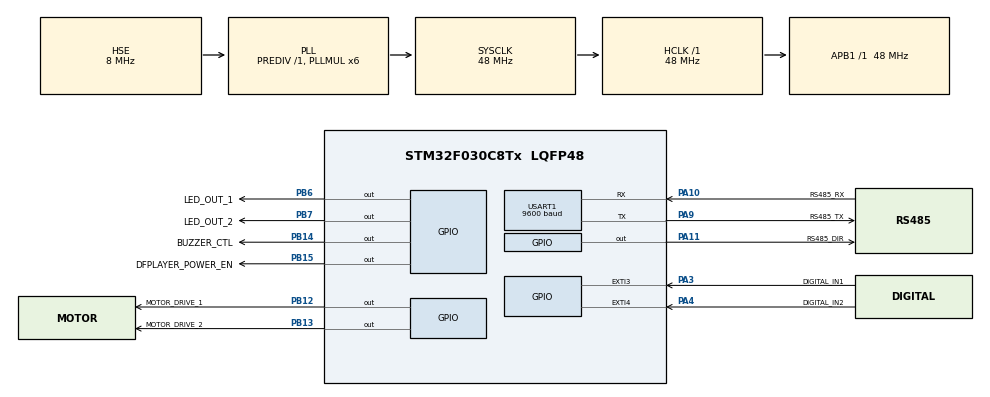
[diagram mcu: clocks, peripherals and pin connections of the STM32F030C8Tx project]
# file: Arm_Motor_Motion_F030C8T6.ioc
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Mcu.Family=STM32F0
Mcu.Name=STM32F030C8Tx
Mcu.Package=LQFP48
NVIC.EXTI2_3_IRQn=true\:0\:0\:false\:false\:true\:true\:true\:true
NVIC.EXTI4_15_IRQn=true\:0\:0\:false\:false\:true\:true\:true\:true
NVIC.USART1_IRQn=true\:0\:0\:false\:false\:true\:true\:true\:true
PA10.GPIO_Label=RS485_RX
PA10.Mode=Asynchronous
PA10.Signal=USART1_RX
PA11.GPIO_Label=RS485_DIR
PA11.Signal=GPIO_Output
PA13.GPIO_Label=TMS
PA13.Mode=Serial_Wire
PA13.Signal=SYS_SWDIO
PA14.GPIO_Label=TCK
PA14.Mode=Serial_Wire
PA14.Signal=SYS_SWCLK
PA3.GPIO_Label=DIGITAL_IN1
PA3.GPIO_ModeDefaultEXTI=GPIO_MODE_IT_RISING_FALLING
PA3.Signal=GPXTI3
PA4.GPIO_Label=DIGITAL_IN2
PA4.Signal=GPXTI4
PA9.GPIO_Label=RS485_TX
PA9.Mode=Asynchronous
PA9.Signal=USART1_TX
PB12.GPIO_Label=MOTOR_DRIVE_1
PB12.Signal=GPIO_Output
PB13.GPIO_Label=MOTOR_DRIVE_2
PB13.Signal=GPIO_Output
PB14.GPIO_Label=BUZZER_CTL
PB14.Signal=GPIO_Output
PB15.GPIO_Label=DFPLAYER_POWER_EN
PB15.Signal=GPIO_Output
PB6.GPIO_Label=LED_OUT_1
PB6.PinState=GPIO_PIN_RESET
PB6.Signal=GPIO_Output
PB7.GPIO_Label=LED_OUT_2
PB7.PinState=GPIO_PIN_RESET
PB7.Signal=GPIO_Output
PF0-OSC_IN.GPIO_Label=OSC_IN
PF0-OSC_IN.Mode=HSE-External-Oscillator
PF0-OSC_IN.Signal=RCC_OSC_IN
PF1-OSC_OUT.GPIO_Label=OSC_OUT
PF1-OSC_OUT.Mode=HSE-External-Oscillator
PF1-OSC_OUT.Signal=RCC_OSC_OUT
ProjectManager.HeapSize=0x200
ProjectManager.StackSize=0x400
ProjectManager.TargetToolchain=STM32CubeIDE
RCC.AHBFreq_Value=48000000
RCC.APB1Freq_Value=48000000
RCC.APB1TimFreq_Value=48000000
RCC.HCLKFreq_Value=48000000
RCC.PLLMUL=RCC_PLL_MUL6
RCC.PLLSourceVirtual=RCC_PLLSOURCE_HSE
RCC.SYSCLKFreq_VALUE=48000000
RCC.SYSCLKSource=RCC_SYSCLKSOURCE_PLLCLK
USART1.BaudRate=9600
USART1.VirtualMode-Asynchronous=VM_ASYNC
board=custom

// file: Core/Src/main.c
/* USER CODE BEGIN Header */
/**
  ******************************************************************************
  * @file           : main.c
  * @brief          : Main program body
  ******************************************************************************
  * @attention
  *
  * Copyright (c) 2024 STMicroelectronics.
  * All rights reserved.
  *
  * This software is licensed under terms that can be found in the LICENSE file
  * in the root directory of this software component.
  * If no LICENSE file comes with this software, it is provided AS-IS.
  *
  ******************************************************************************
  */
/* USER CODE END Header */
#include "main.h"

UART_HandleTypeDef huart1;

void SystemClock_Config(void);
static void MX_GPIO_Init(void);
static void MX_USART1_UART_Init(void);

int main(void)
{

  /* MCU Configuration--------------------------------------------------------*/

  /* Reset of all peripherals, Initializes the Flash interface and the Systick. */
  HAL_Init();

  /* Configure the system clock */
  SystemClock_Config();

  /* Initialize all configured peripherals */
  MX_GPIO_Init();
  MX_USART1_UART_Init();
  /* USER CODE BEGIN 2 */
  motor_motion_init();
  /* USER CODE END 2 */

  /* Infinite loop */
  while (1)
  {

    /* USER CODE BEGIN 3 */
	  motor_motion_control();
  }
  /* USER CODE END 3 */
}

void SystemClock_Config(void)
{
  RCC_OscInitTypeDef RCC_OscInitStruct = {0};
  RCC_ClkInitTypeDef RCC_ClkInitStruct = {0};
  RCC_PeriphCLKInitTypeDef PeriphClkInit = {0};

  /** Initializes the RCC Oscillators according to the specified parameters
  * in the RCC_OscInitTypeDef structure.
  */
  RCC_OscInitStruct.OscillatorType = RCC_OSCILLATORTYPE_HSE;
  RCC_OscInitStruct.HSEState = RCC_HSE_ON;
  RCC_OscInitStruct.PLL.PLLState = RCC_PLL_ON;
  RCC_OscInitStruct.PLL.PLLSource = RCC_PLLSOURCE_HSE;
  RCC_OscInitStruct.PLL.PLLMUL = RCC_PLL_MUL6;
  RCC_OscInitStruct.PLL.PREDIV = RCC_PREDIV_DIV1;
  if (HAL_RCC_OscConfig(&RCC_OscInitStruct) != HAL_OK)
  {
    Error_Handler();
  }

  /** Initializes the CPU, AHB and APB buses clocks
  */
  RCC_ClkInitStruct.ClockType = RCC_CLOCKTYPE_HCLK|RCC_CLOCKTYPE_SYSCLK
                              |RCC_CLOCKTYPE_PCLK1;
  RCC_ClkInitStruct.SYSCLKSource = RCC_SYSCLKSOURCE_PLLCLK;
  RCC_ClkInitStruct.AHBCLKDivider = RCC_SYSCLK_DIV1;
  RCC_ClkInitStruct.APB1CLKDivider = RCC_HCLK_DIV1;

  if (HAL_RCC_ClockConfig(&RCC_ClkInitStruct, FLASH_LATENCY_1) != HAL_OK)
  {
    Error_Handler();
  }
  PeriphClkInit.PeriphClockSelection = RCC_PERIPHCLK_USART1;
  PeriphClkInit.Usart1ClockSelection = RCC_USART1CLKSOURCE_PCLK1;
  if (HAL_RCCEx_PeriphCLKConfig(&PeriphClkInit) != HAL_OK)
  {
    Error_Handler();
  }
}

static void MX_USART1_UART_Init(void)
{

  huart1.Instance = USART1;
  huart1.Init.BaudRate = 9600;
  huart1.Init.WordLength = UART_WORDLENGTH_8B;
  huart1.Init.StopBits = UART_STOPBITS_1;
  huart1.Init.Parity = UART_PARITY_NONE;
  huart1.Init.Mode = UART_MODE_TX_RX;
  huart1.Init.HwFlowCtl = UART_HWCONTROL_NONE;
  huart1.Init.OverSampling = UART_OVERSAMPLING_16;
  huart1.Init.OneBitSampling = UART_ONE_BIT_SAMPLE_DISABLE;
  huart1.AdvancedInit.AdvFeatureInit = UART_ADVFEATURE_NO_INIT;
  if (HAL_UART_Init(&huart1) != HAL_OK)
  {
    Error_Handler();
  }

}

static void MX_GPIO_Init(void)
{
  GPIO_InitTypeDef GPIO_InitStruct = {0};

  /* GPIO Ports Clock Enable */
  __HAL_RCC_GPIOF_CLK_ENABLE();
  __HAL_RCC_GPIOA_CLK_ENABLE();
  __HAL_RCC_GPIOB_CLK_ENABLE();

  /*Configure GPIO pin Output Level */
  HAL_GPIO_WritePin(GPIOB, MOTOR_DRIVE_1_Pin|MOTOR_DRIVE_2_Pin|BUZZER_CTL_Pin|DFPLAYER_POWER_EN_Pin
                          |LED_OUT_1_Pin|LED_OUT_2_Pin, GPIO_PIN_RESET);

  /*Configure GPIO pin Output Level */
  HAL_GPIO_WritePin(RS485_DIR_GPIO_Port, RS485_DIR_Pin, GPIO_PIN_RESET);

  /*Configure GPIO pin : DIGITAL_IN1_Pin */
  GPIO_InitStruct.Pin = DIGITAL_IN1_Pin;
  GPIO_InitStruct.Mode = GPIO_MODE_IT_RISING_FALLING;
  GPIO_InitStruct.Pull = GPIO_NOPULL;
  HAL_GPIO_Init(DIGITAL_IN1_GPIO_Port, &GPIO_InitStruct);

  /*Configure GPIO pin : DIGITAL_IN2_Pin */
  GPIO_InitStruct.Pin = DIGITAL_IN2_Pin;
  GPIO_InitStruct.Mode = GPIO_MODE_IT_RISING;
  GPIO_InitStruct.Pull = GPIO_NOPULL;
  HAL_GPIO_Init(DIGITAL_IN2_GPIO_Port, &GPIO_InitStruct);

  /*Configure GPIO pins : MOTOR_DRIVE_1_Pin MOTOR_DRIVE_2_Pin BUZZER_CTL_Pin DFPLAYER_POWER_EN_Pin
                           LED_OUT_1_Pin LED_OUT_2_Pin */
  GPIO_InitStruct.Pin = MOTOR_DRIVE_1_Pin|MOTOR_DRIVE_2_Pin|BUZZER_CTL_Pin|DFPLAYER_POWER_EN_Pin
                          |LED_OUT_1_Pin|LED_OUT_2_Pin;
  GPIO_InitStruct.Mode = GPIO_MODE_OUTPUT_PP;
  GPIO_InitStruct.Pull = GPIO_NOPULL;
  GPIO_InitStruct.Speed = GPIO_SPEED_FREQ_LOW;
  HAL_GPIO_Init(GPIOB, &GPIO_InitStruct);

  /*Configure GPIO pin : RS485_DIR_Pin */
  GPIO_InitStruct.Pin = RS485_DIR_Pin;
  GPIO_InitStruct.Mode = GPIO_MODE_OUTPUT_PP;
  GPIO_InitStruct.Pull = GPIO_NOPULL;
  GPIO_InitStruct.Speed = GPIO_SPEED_FREQ_LOW;
  HAL_GPIO_Init(RS485_DIR_GPIO_Port, &GPIO_InitStruct);

  /* EXTI interrupt init*/
  HAL_NVIC_SetPriority(EXTI2_3_IRQn, 0, 0);
  HAL_NVIC_EnableIRQ(EXTI2_3_IRQn);

  HAL_NVIC_SetPriority(EXTI4_15_IRQn, 0, 0);
  HAL_NVIC_EnableIRQ(EXTI4_15_IRQn);

}

void Error_Handler(void)
{
  __disable_irq();
  while (1)
  {
  }
}
